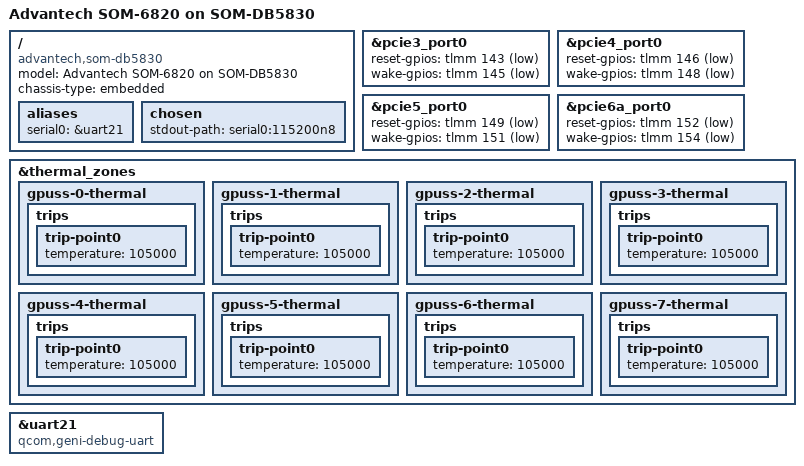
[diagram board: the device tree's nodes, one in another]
// SPDX-License-Identifier: BSD-3-Clause
/*
 * Copyright (c) Qualcomm Technologies, Inc. and/or its subsidiaries.
 *
 * SoM: https://advdownload.advantech.com.cn/productfile/PIS/SOM-6820/file/SOM-6820_DS(052925)20250529110758.pdf
 * carrier board: https://www.advantech.com.cn/zh-cn/products/1-fc23ff/som-db5830/mod_16b1a718-27d6-4a4c-8684-e8f2a8e9c57b
 */

/dts-v1/;

#include "hamoa-advantech-som-6820.dtsi"

/ {
	model = "Advantech SOM-6820 on SOM-DB5830";
	compatible = "advantech,som-db5830", "advantech,som-6820",
		     "qcom,iq-x7181-evk-som", "qcom,x1e80100";
	chassis-type = "embedded";

	aliases {
		serial0 = &uart21;
	};

	chosen {
		stdout-path = "serial0:115200n8";
	};

};

&pcie3_port0 {
	reset-gpios = <&tlmm 143 GPIO_ACTIVE_LOW>;
	wake-gpios = <&tlmm 145 GPIO_ACTIVE_LOW>;
};

&pcie4_port0 {
	reset-gpios = <&tlmm 146 GPIO_ACTIVE_LOW>;
	wake-gpios = <&tlmm 148 GPIO_ACTIVE_LOW>;
};

&pcie5_port0 {
	reset-gpios = <&tlmm 149 GPIO_ACTIVE_LOW>;
	wake-gpios = <&tlmm 151 GPIO_ACTIVE_LOW>;
};

&pcie6a_port0 {
	reset-gpios = <&tlmm 152 GPIO_ACTIVE_LOW>;
	wake-gpios = <&tlmm 154 GPIO_ACTIVE_LOW>;
};

&thermal_zones {
	gpuss-0-thermal {
		trips {
			trip-point0 {
				temperature = <105000>;
			};
		};
	};

	gpuss-1-thermal {
		trips {
			trip-point0 {
				temperature = <105000>;
			};
		};
	};

	gpuss-2-thermal {
		trips {
			trip-point0 {
				temperature = <105000>;
			};
		};
	};

	gpuss-3-thermal {
		trips {
			trip-point0 {
				temperature = <105000>;
			};
		};
	};

	gpuss-4-thermal {
		trips {
			trip-point0 {
				temperature = <105000>;
			};
		};
	};

	gpuss-5-thermal {
		trips {
			trip-point0 {
				temperature = <105000>;
			};
		};
	};

	gpuss-6-thermal {
		trips {
			trip-point0 {
				temperature = <105000>;
			};
		};
	};

	gpuss-7-thermal {
		trips {
			trip-point0 {
				temperature = <105000>;
			};
		};
	};
};

&uart21 {
	compatible = "qcom,geni-debug-uart";

	status = "okay";
};
